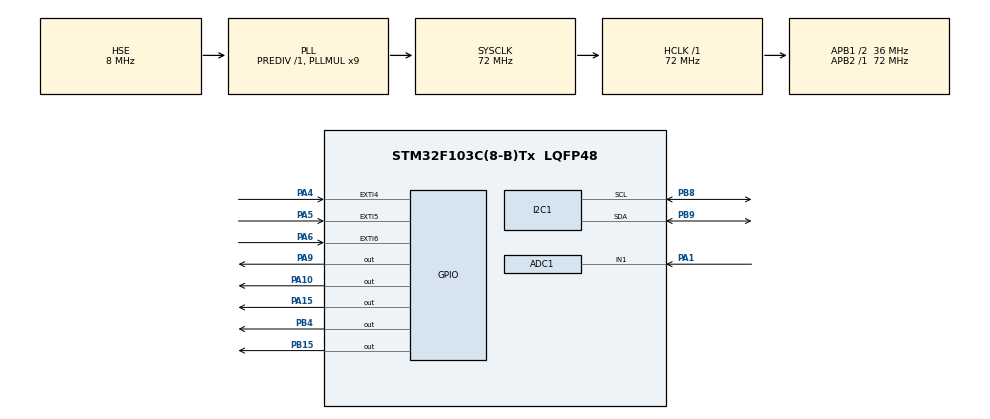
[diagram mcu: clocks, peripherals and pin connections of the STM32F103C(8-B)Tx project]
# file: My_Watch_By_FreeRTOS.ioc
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ADC1.Channel-0\#ChannelRegularConversion=ADC_CHANNEL_1
ADC1.ContinuousConvMode=ENABLE
ADC1.NbrOfConversionFlag=1
ADC1.Rank-0\#ChannelRegularConversion=1
ADC1.SamplingTime-0\#ChannelRegularConversion=ADC_SAMPLETIME_13CYCLES_5
ADC1.master=1
Mcu.Family=STM32F1
Mcu.Name=STM32F103C(8-B)Tx
Mcu.Package=LQFP48
NVIC.EXTI4_IRQn=true\:5\:0\:true\:false\:true\:true\:true\:true
NVIC.EXTI9_5_IRQn=true\:5\:0\:true\:false\:true\:true\:true\:true
NVIC.PriorityGroup=NVIC_PRIORITYGROUP_4
NVIC.TIM4_IRQn=true\:15\:0\:false\:false\:true\:false\:true\:true
NVIC.TimeBase=TIM4_IRQn
NVIC.TimeBaseIP=TIM4
PA1.Signal=ADCx_IN1
PA10.GPIO_ModeDefaultOutputPP=GPIO_MODE_OUTPUT_PP
PA10.GPIO_PuPd=GPIO_NOPULL
PA10.PinState=GPIO_PIN_RESET
PA10.Signal=GPIO_Output
PA13.Mode=Serial_Wire
PA13.Signal=SYS_JTMS-SWDIO
PA14.Mode=Serial_Wire
PA14.Signal=SYS_JTCK-SWCLK
PA15.GPIO_ModeDefaultOutputPP=GPIO_MODE_OUTPUT_OD
PA15.GPIO_PuPd=GPIO_PULLUP
PA15.PinState=GPIO_PIN_SET
PA15.Signal=GPIO_Output
PA4.GPIO_ModeDefaultEXTI=GPIO_MODE_IT_FALLING
PA4.GPIO_PuPd=GPIO_PULLUP
PA4.Signal=GPXTI4
PA5.GPIO_ModeDefaultEXTI=GPIO_MODE_IT_FALLING
PA5.GPIO_PuPd=GPIO_PULLUP
PA5.Signal=GPXTI5
PA6.GPIO_ModeDefaultEXTI=GPIO_MODE_IT_FALLING
PA6.GPIO_PuPd=GPIO_PULLUP
PA6.Signal=GPXTI6
PA9.GPIO_PuPd=GPIO_NOPULL
PA9.Signal=GPIO_Output
PB15.PinState=GPIO_PIN_RESET
PB15.Signal=GPIO_Output
PB4.GPIO_PuPd=GPIO_PULLDOWN
PB4.PinState=GPIO_PIN_RESET
PB4.Signal=GPIO_Output
PB8.Mode=I2C
PB8.Signal=I2C1_SCL
PB9.Mode=I2C
PB9.Signal=I2C1_SDA
PD0-OSC_IN.Mode=HSE-External-Oscillator
PD0-OSC_IN.Signal=RCC_OSC_IN
PD1-OSC_OUT.Mode=HSE-External-Oscillator
PD1-OSC_OUT.Signal=RCC_OSC_OUT
ProjectManager.HeapSize=0x200
ProjectManager.StackSize=0x400
ProjectManager.TargetToolchain=MDK-ARM V5
RCC.ADCPresc=RCC_ADCPCLK2_DIV6
RCC.AHBFreq_Value=72000000
RCC.APB1CLKDivider=RCC_HCLK_DIV2
RCC.APB1Freq_Value=36000000
RCC.APB1TimFreq_Value=72000000
RCC.APB2Freq_Value=72000000
RCC.APB2TimFreq_Value=72000000
RCC.HCLKFreq_Value=72000000
RCC.PLLMUL=RCC_PLL_MUL9
RCC.PLLSourceVirtual=RCC_PLLSOURCE_HSE
RCC.SYSCLKFreq_VALUE=72000000
RCC.SYSCLKSource=RCC_SYSCLKSOURCE_PLLCLK
RCC.USBFreq_Value=72000000
SH.ADCx_IN1.0=ADC1_IN1,IN1
VP_SYS_VS_tim4.Mode=TIM4
board=custom

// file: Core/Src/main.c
/* USER CODE BEGIN Header */
/**
  ******************************************************************************
  * @file           : main.c
  * @brief          : Main program body
  ******************************************************************************
  * @attention
  *
  * Copyright (c) 2025 STMicroelectronics.
  * All rights reserved.
  *
  * This software is licensed under terms that can be found in the LICENSE file
  * in the root directory of this software component.
  * If no LICENSE file comes with this software, it is provided AS-IS.
  *
  ******************************************************************************
  */
/* USER CODE END Header */
#include "main.h"
#include "adc.h"
#include "i2c.h"
#include "gpio.h"

/* USER CODE BEGIN Includes */
#include "FreeRTOSInit.h"
#include "oled.h"
#include "Delay.h"
/* USER CODE END Includes */

void SystemClock_Config(void);

/* USER CODE BEGIN 0 */
//void DWT_Init(void)
//{
//    CoreDebug->DEMCR |= CoreDebug_DEMCR_TRCENA_Msk; // 使能 DWT 计数器
//    DWT->CYCCNT = 0;  // 计数器清零
//    DWT->CTRL |= DWT_CTRL_CYCCNTENA_Msk; // 使能 CYCCNT 计数功能
//}
/* USER CODE END 0 */

int main(void)
{

  /* MCU Configuration--------------------------------------------------------*/

  /* Reset of all peripherals, Initializes the Flash interface and the Systick. */
  HAL_Init();

  /* Configure the system clock */
  SystemClock_Config();

  /* Initialize all configured peripherals */
  MX_GPIO_Init();
  MX_I2C1_Init();
  MX_ADC1_Init();
  /* USER CODE BEGIN 2 */
//	DWT_Init();
  /* USER CODE END 2 */

  /* Infinite loop */
  /* USER CODE BEGIN WHILE */
	OLED_Init();
	OLED_Clear();
	FreeRTOS_Init();
  while (1)
  {
    /* USER CODE END WHILE */

    /* USER CODE BEGIN 3 */
//		OLED_ShowNum(0, 0, a, 3, 16, 0);
//		delay_ms(1000);
//		a++;
	}
  /* USER CODE END 3 */
}

void SystemClock_Config(void)
{
  RCC_OscInitTypeDef RCC_OscInitStruct = {0};
  RCC_ClkInitTypeDef RCC_ClkInitStruct = {0};
  RCC_PeriphCLKInitTypeDef PeriphClkInit = {0};

  /** Initializes the RCC Oscillators according to the specified parameters
  * in the RCC_OscInitTypeDef structure.
  */
  RCC_OscInitStruct.OscillatorType = RCC_OSCILLATORTYPE_HSE;
  RCC_OscInitStruct.HSEState = RCC_HSE_ON;
  RCC_OscInitStruct.HSEPredivValue = RCC_HSE_PREDIV_DIV1;
  RCC_OscInitStruct.HSIState = RCC_HSI_ON;
  RCC_OscInitStruct.PLL.PLLState = RCC_PLL_ON;
  RCC_OscInitStruct.PLL.PLLSource = RCC_PLLSOURCE_HSE;
  RCC_OscInitStruct.PLL.PLLMUL = RCC_PLL_MUL9;
  if (HAL_RCC_OscConfig(&RCC_OscInitStruct) != HAL_OK)
  {
    Error_Handler();
  }

  /** Initializes the CPU, AHB and APB buses clocks
  */
  RCC_ClkInitStruct.ClockType = RCC_CLOCKTYPE_HCLK|RCC_CLOCKTYPE_SYSCLK
                              |RCC_CLOCKTYPE_PCLK1|RCC_CLOCKTYPE_PCLK2;
  RCC_ClkInitStruct.SYSCLKSource = RCC_SYSCLKSOURCE_PLLCLK;
  RCC_ClkInitStruct.AHBCLKDivider = RCC_SYSCLK_DIV1;
  RCC_ClkInitStruct.APB1CLKDivider = RCC_HCLK_DIV2;
  RCC_ClkInitStruct.APB2CLKDivider = RCC_HCLK_DIV1;

  if (HAL_RCC_ClockConfig(&RCC_ClkInitStruct, FLASH_LATENCY_2) != HAL_OK)
  {
    Error_Handler();
  }
  PeriphClkInit.PeriphClockSelection = RCC_PERIPHCLK_ADC;
  PeriphClkInit.AdcClockSelection = RCC_ADCPCLK2_DIV6;
  if (HAL_RCCEx_PeriphCLKConfig(&PeriphClkInit) != HAL_OK)
  {
    Error_Handler();
  }
}

/* USER CODE BEGIN 4 */
void Escape_Stop_Mode(void)  /* 退出停止模式 */
{
	SystemInit();
  HAL_Init();
	SystemClock_Config();
	MX_GPIO_Init();
}
/* USER CODE END 4 */

void HAL_TIM_PeriodElapsedCallback(TIM_HandleTypeDef *htim)
{
  if (htim->Instance == TIM4)
  {
    HAL_IncTick();
  }
}

void Error_Handler(void)
{
  __disable_irq();
  while (1)
  {
  }
}
